# YTM32B1ME0 register map
Vendor: YTMicro; File version: 1.6
CPU: CM33 r0p4, little endian, MPU, FPU, 2 interrupt priority bits
Registers are 32-bit, read-write, reset 0x0 unless marked. A register's access mark holds for its fields unless they carry their own. Offsets are from the block's base; [hi:lo] are bit positions; {n}, {i} and the like mark numbered series; 'fields as' and 'values as' point back to an identical list.

## SCU — System Clock Unit of Microcontroller
Base 0x4007C000; register names take the prefix SCU_
0x00 CLKS — The register contains system clock source selection bit, the system clock source is the root of system clock divider which generates Core/Platform Clock, Fast Bus Clock and Slow Bus Clock.
  [1:0] CLKSRCSEL — System Clock Source selection bits.
    0=Select FIRC as system clock source; 1=Select PLL as system clock source; 2=Select FXOSC as system clock source; 3=Select SIRC as system clock source
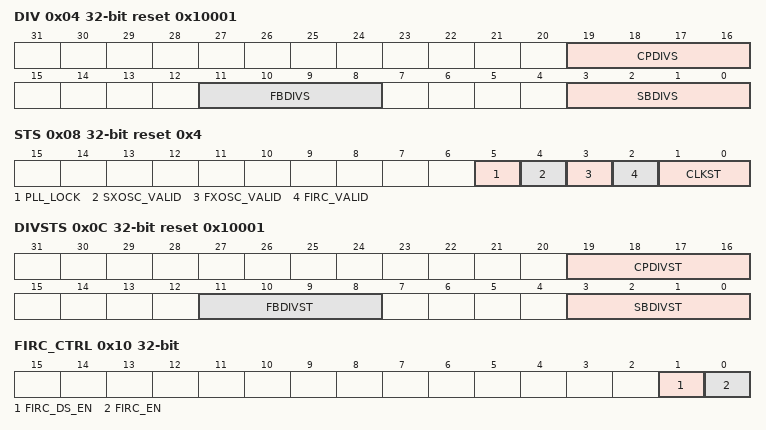
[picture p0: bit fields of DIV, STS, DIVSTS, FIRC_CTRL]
0x04 DIV reset 0x10001 — This register controls the system clock divider which generates Core Platform Clock, Fast Bus Clock and Slow Bus Clock.
  [all] fields
    {v}=Divide by {v+1} (v=0..15)
  [19:16] CPDIVS — Core Platform Clock Divider Value
  [11:8] FBDIVS — Fast Bus Clock Divider Value
  [3:0] SBDIVS — Slow Bus Clock Divider Value
0x08 STS ro reset 0x4 — System Clock Unit Status register
  [5] PLL_LOCK — PLL Lock bit.
    0=PLL unlocked; 1=PLL locked
  [4] SXOSC_VALID — SXOSC Clock valid.
    0=SXOSC Clock invalid; 1=SXOSC Clock valid
  [3] FXOSC_VALID — FXOSC Clock valid.
    0=FXOSC Clock invalid; 1=FXOSC Clock valid
  [2] FIRC_VALID — FIRC Clock valid.
    0=FIRC Clock invalid; 1=FIRC Clock valid
  [1:0] CLKST — System Clock Source selection status bits.
    0=FIRC is selected as system clock source; 1=PLL is selected as system clock source; 2=FXOSC is selected as system clock source; 3=SIRC is selected as system clock source
0x0C DIVSTS ro reset 0x10001 — System Clock Unit clock divider status, check this register after any change of divider value.
  [all] fields
    {v}=Divide by {v+1} (v=0..15)
  [19:16] CPDIVST — Core Platform Clock Divider Value
  [11:8] FBDIVST — Fast Bus Clock Divider Value
  [3:0] SBDIVST — Slow Bus Clock Divider Value
0x10 FIRC_CTRL — FIRC control register
  [1] FIRC_DS_EN — Enable FIRC when chip enters Deepsleep mode.
    0=Disable FIRC when chip enters Deepsleep mode; 1=Enable FIRC when chip enters Deepsleep mode
  [0] FIRC_EN — Enable FIRC regardless it is selected as system clock source.
    0=Disable FIRC if it is not selected as system clock source; 1=Enable FIRC regardless it is selected as system clock or not
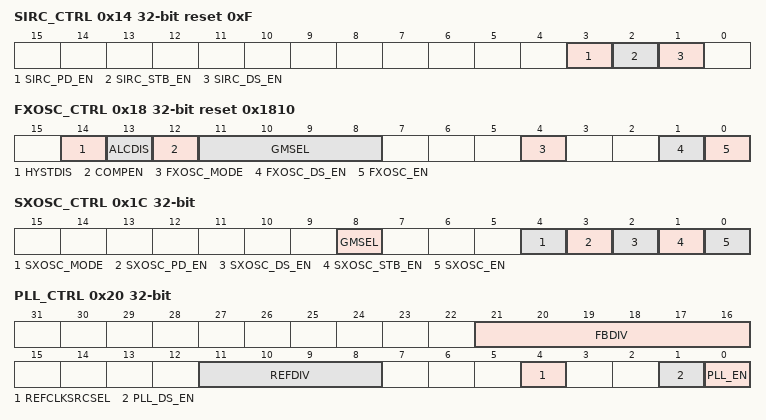
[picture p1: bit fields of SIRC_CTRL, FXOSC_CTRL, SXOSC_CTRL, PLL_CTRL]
0x14 SIRC_CTRL reset 0xF — SIRC control register
  [3] SIRC_PD_EN — Enable SIRC when chip enters Powerdown mode.
    0=Disable SIRC when chip enters Powerdown mode; 1=Enable SIRC when chip enters Powerdown mode
  [2] SIRC_STB_EN — Enable SIRC when chip enters Standby mode.
    0=Disable SIRC when chip enters Standby mode; 1=Enable SIRC when chip enters Standby mode
  [1] SIRC_DS_EN — Enable SIRC when chip enters Deepsleep mode.
    0=Disable SIRC when chip enters Deepsleep mode; 1=Enable SIRC when chip enters Deepsleep mode
0x18 FXOSC_CTRL reset 0x1810 — FXOSC control register
  [14] HYSTDIS — This bit should not be changed when FXOSC_VALID is high
  [13] ALCDIS — This bit should not be changed when FXOSC_VALID is high
  [12] COMPEN — Comp enable bit, this bit should be high when crystal mode is used, and it should be low when bypass mode is used, and it should not be changed when FXOSC_VALID is high
  [11:8] GMSEL — Gain select bit, higher gain value results higher power and better performance, it only impact FXOSC crystal mode, and it should not be changed when FXOSC_VALID is high
  [4] FXOSC_MODE — Select FXOSC crystal mode or bypass mode, it should not be changed when FXOSC_VALID is high
    0=FXOSC bypass mode; 1=FXOSC crystal mode
  [1] FXOSC_DS_EN — Enable FXOSC when chip enters Deepsleep mode.
    0=Disable FXOSC when chip enters Deepsleep mode; 1=Enable FXOSC when chip enters Deepsleep mode
  [0] FXOSC_EN — Enable Fast Crystal Oscillator(FXOSC) regardless it is selected as system clock source.
    0=Disable FXOSC if it is not selected as system clock source; 1=Enable FXOSC regardless it is selected as system clock or not
0x1C SXOSC_CTRL — SXOSC control register
  [8] GMSEL — SXOSC Gain select bit
  [4] SXOSC_MODE — Select SXOSC oscillator mode or bypass mode
    0=SXOSC bypass mode; 1=SXOSC crystal mode
  [3] SXOSC_PD_EN — Enable SXOSC when chip enters Powerdown mode.
    0=Disable SXOSC when chip enters Standby mode; 1=Enable SXOSC when chip enters Standby mode
  [2] SXOSC_DS_EN — Enable SXOSC when chip enters Deepsleep mode.
    0=Disable SXOSC when chip enters Deepsleep mode; 1=Enable SXOSC when chip enters Deepsleep mode
  [1] SXOSC_STB_EN — Enable SXOSC when chip enters Standby mode.
    values as SXOSC_PD_EN
  [0] SXOSC_EN — Enable/Disable SXOSC
    0=Disable SXOSC; 1=Enable SXOSC
0x20 PLL_CTRL — System Clock Unit PLL control register, changes to this register should be done when PLL is disable to prevent glitches to system clock source.
  [21:16] FBDIV — PLL feedback div value
  [11:8] REFDIV — PLL reference clock div value
  [4] REFCLKSRCSEL — PLL reference clock source select bit
    0=Select FXOSC as PLL reference clock; 1=Select FIRC as PLL reference clock
  [1] PLL_DS_EN — Enable PLL when chip enters Deepsleep mode.
    0=Disable PLL when chip enters Deepsleep mode; 1=Enable PLL when chip enters Deepsleep mode
  [0] PLL_EN — Enable PLL regardless it is selected as system clock source.
    0=Disable PLL if it is not selected as system clock source; 1=Enable PLL regardless it is selected as system clock or not
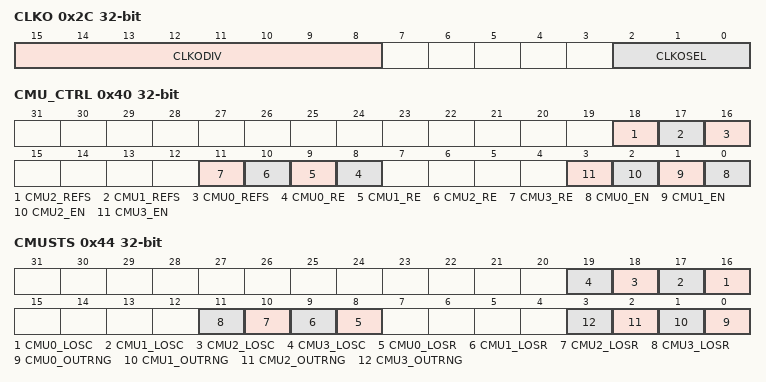
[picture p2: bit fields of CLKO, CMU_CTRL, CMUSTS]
0x2C CLKO — This register is to select the clock sources to output to chip IOs for external use.
  [15:8] CLKODIV — Clock output divider value. Only support even divider. \begin{itemize}[label={}, leftmargin=*] \itemsep1pt\parskip0pt\parsep0pt \item 00000000b - DIV disable \item 00000001b - DIV disable \item xxxxxx1xb - DIV as the value \vspace*{-\baselineskip} \end{itemize}
  [2:0] CLKOSEL — Clock output source select.
    0=None clock select to output; 1=FIRC clock output; 2=SIRC clock output; 3=FXOSC clock output; 4=SXOSC clock output; 5=PLL clock output; 6=TRNG ring oscillator otuput; 7=Core clock output
0x40 CMU_CTRL — System Clock Unit Clock Monitor Unit control register
  [18] CMU2_REFS — CMU2 reference clock selected
    0=SIRC selected as reference clock of CMU; 1=FXOSC selected as reference clock of CMU
  [17] CMU1_REFS — CMU1 reference clock selected
    values as CMU2_REFS
  [16] CMU0_REFS — CMU0 reference clock selected
    values as CMU2_REFS
  [n+8] CMU{n}_RE (n=0..3) — CMU{n} reset enable
    0=Reset disable when CMU event happen; 1=Reset enable when CMU event happen
  [n] CMU{n}_EN (n=0..3) — CMU{n} enable
    0=CMU disable; 1=CMU enable
0x44 CMUSTS — System Clock Unit Clock Monitor Unit status register
  [n+16] CMU{n}_LOSC (n=0..3) — CMU{n} loss of clock
  [n+8] CMU{n}_LOSR (n=0..3) — CMU{n} loss of reference clock
  [n] CMU{n}_OUTRNG (n=0..3) — CMU{n} clock out of range
{0x48+8i} CMUCMP{i}_HIGH reset 0xFFFF (i=0..3) — System Clock Unit Clock Monitor High Comparison Value Register
  [15:0] VAL
{0x4C+8i} CMUCMP{i}_LOW (i=0..3) — System Clock Unit Clock Monitor Low Comparison Value Register
  [15:0] VAL
